VERSION ""
NS_ :

BS_:

BU_: BMS DCM DIM FSM GSM PDM DEBUG

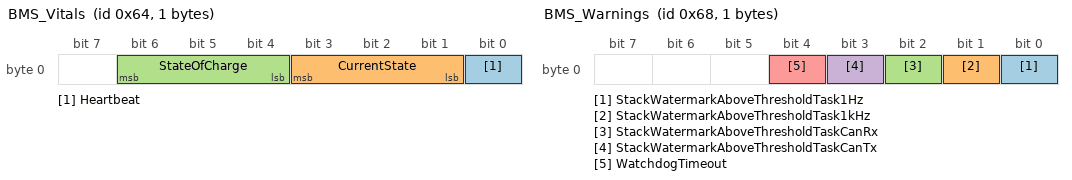
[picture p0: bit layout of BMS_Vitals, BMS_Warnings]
BO_ 100 BMS_Vitals: 1 BMS
SG_ Heartbeat : 0|1@1+ (1,0) [0|1] "" DEBUG,PDM
SG_ CurrentState : 1|3@1+ (1,0) [0|4] "" DEBUG,PDM
SG_ StateOfCharge : 4|3@1+ (14.285714285714286,0) [0|100] "" DEBUG,PDM

BO_ 101 BMS_CanFifoOverflow: 8 BMS
SG_ TxOverflowCount : 0|32@1+ (1,0) [0|4294967295] "" DEBUG
SG_ RxOverflowCount : 32|32@1+ (1,0) [0|4294967295] "" DEBUG

BO_ 103 BMS_WatchdogTimeout: 1 BMS
SG_ TaskName : 0|3@1+ (1,0) [0|4] "" DEBUG

BO_ 104 BMS_Warnings: 1 BMS
SG_ StackWatermarkAboveThresholdTask1Hz : 0|1@1+ (1,0) [0|1] "" DEBUG
SG_ StackWatermarkAboveThresholdTask1kHz : 1|1@1+ (1,0) [0|1] "" DEBUG
SG_ StackWatermarkAboveThresholdTaskCanRx : 2|1@1+ (1,0) [0|1] "" DEBUG
SG_ StackWatermarkAboveThresholdTaskCanTx : 3|1@1+ (1,0) [0|1] "" DEBUG
SG_ WatchdogTimeout : 4|1@1+ (1,0) [0|1] "" DEBUG

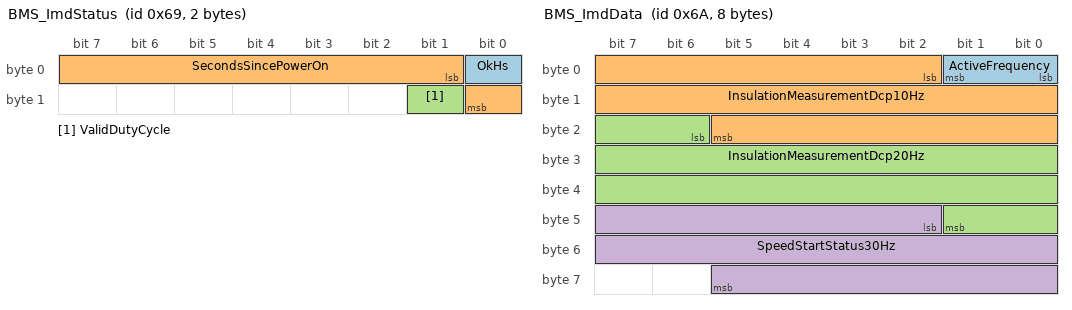
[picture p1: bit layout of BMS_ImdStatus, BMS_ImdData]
BO_ 105 BMS_ImdStatus: 2 BMS
SG_ OkHs : 0|1@1+ (1,0) [0|1] "" DEBUG
SG_ SecondsSincePowerOn : 1|8@1+ (1.0,0) [0|255] "Seconds" DEBUG
SG_ ValidDutyCycle : 9|1@1+ (1,0) [0|1] "" DEBUG

BO_ 106 BMS_ImdData: 8 BMS
SG_ ActiveFrequency : 0|2@1+ (6.666666666666667,0) [0|20] "Hz" DEBUG
SG_ InsulationMeasurementDcp10Hz : 2|20@1+ (0.1,0) [0|65535] "kOhm" DEBUG
SG_ InsulationMeasurementDcp20Hz : 22|20@1+ (0.1,0) [0|65535] "kOhm" DEBUG
SG_ SpeedStartStatus30Hz : 42|20@1+ (0.1,0) [0|65535] "" DEBUG

BO_ 107 BMS_ImdPwmOutput: 1 BMS
SG_ DutyCycle : 0|3@1+ (14.285714285714286,0) [0|100] "%" DEBUG
SG_ Frequency : 3|4@1+ (6.666666666666667,0) [0|100] "Hz" DEBUG

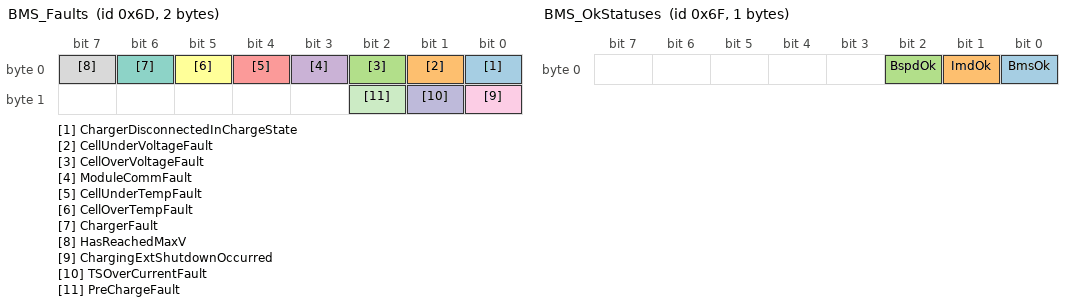
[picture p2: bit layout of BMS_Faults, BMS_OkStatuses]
BO_ 109 BMS_Faults: 2 BMS
SG_ ChargerDisconnectedInChargeState : 0|1@1+ (1,0) [0|1] "" DEBUG
SG_ CellUnderVoltageFault : 1|1@1+ (1,0) [0|1] "" DEBUG
SG_ CellOverVoltageFault : 2|1@1+ (1,0) [0|1] "" DEBUG
SG_ ModuleCommFault : 3|1@1+ (1,0) [0|1] "" DEBUG
SG_ CellUnderTempFault : 4|1@1+ (1,0) [0|1] "" DEBUG
SG_ CellOverTempFault : 5|1@1+ (1,0) [0|1] "" DEBUG
SG_ ChargerFault : 6|1@1+ (1,0) [0|1] "" DEBUG
SG_ HasReachedMaxV : 7|1@1+ (1,0) [0|1] "" DEBUG
SG_ ChargingExtShutdownOccurred : 8|1@1+ (1,0) [0|1] "" DEBUG
SG_ TSOverCurrentFault : 9|1@1+ (1,0) [0|1] "" DEBUG
SG_ PreChargeFault : 10|1@1+ (1,0) [0|1] "" DEBUG

BO_ 110 BMS_Charger: 1 BMS
SG_ IsConnected : 0|1@1+ (1,0) [0|1] "" DEBUG
SG_ IsChargingComplete : 1|1@1+ (1,0) [0|1] "" DEBUG

BO_ 111 BMS_OkStatuses: 1 BMS
SG_ BmsOk : 0|1@1+ (1,0) [0|1] "" DEBUG,DIM
SG_ ImdOk : 1|1@1+ (1,0) [0|1] "" DEBUG,DIM
SG_ BspdOk : 2|1@1+ (1,0) [0|1] "" DEBUG,DIM

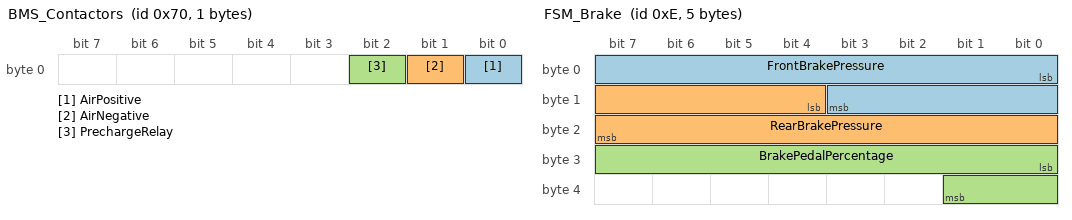
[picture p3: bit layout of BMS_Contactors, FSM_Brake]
BO_ 112 BMS_Contactors: 1 BMS
SG_ AirPositive : 0|1@1+ (1,0) [0|1] "" DEBUG,PDM
SG_ AirNegative : 1|1@1+ (1,0) [0|1] "" DEBUG,PDM
SG_ PrechargeRelay : 2|1@1+ (1,0) [0|1] "" DEBUG,PDM
BO_ 151 FSM_APPs: 3 FSM
SG_ PappsMappedPedalPercentage : 0|10@1+ (0.1,0) [0|100] "%" DEBUG
SG_ SappsMappedPedalPercentage : 10|10@1+ (0.1,0) [0|100] "%" DEBUG

BO_ 113 BMS_MotorShutdownErrors: 1 BMS
SG_ BmsDummyMotorShutdown : 0|1@1+ (1,0) [0|1] "" DEBUG
BO_ 14 FSM_Brake: 5 FSM
SG_ FrontBrakePressure : 0|12@1+ (1,0) [0|2500] "psi" DEBUG
SG_ RearBrakePressure : 12|12@1+ (1,0) [0|2500] "psi" DEBUG
SG_ BrakePedalPercentage : 24|10@1+ (0.1,0) [0|100] "%" DEBUG

BO_ 114 BMS_CellTemperatures: 3 BMS
SG_ MinCellTemperature : 0|10@1+ (0.1,0) [0|100] "degC" DEBUG
SG_ MaxCellTemperature : 10|10@1+ (0.1,0) [0|100] "degC" DEBUG
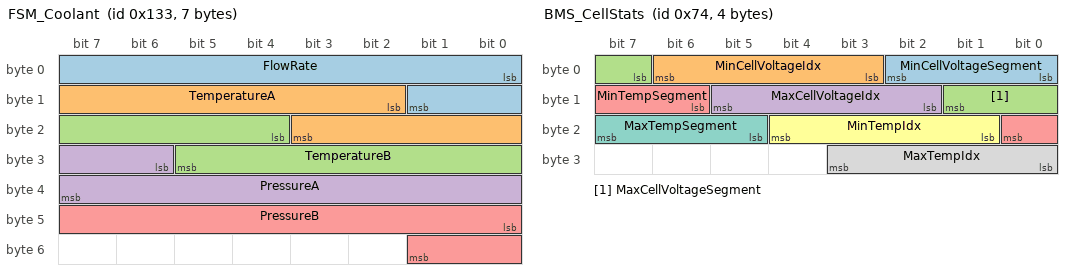
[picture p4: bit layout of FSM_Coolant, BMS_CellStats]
BO_ 307 FSM_Coolant: 7 FSM
SG_ FlowRate : 0|10@1+ (0.1,0) [0|100] "L/min" DEBUG
SG_ TemperatureA : 10|10@1+ (0.1,0) [0|100] "°C" DEBUG
SG_ TemperatureB : 20|10@1+ (0.1,0) [0|100] "°C" DEBUG
SG_ PressureA : 30|10@1+ (0.1,0) [0|100] "psi" DEBUG
SG_ PressureB : 40|10@1+ (0.1,0) [0|100] "psi" DEBUG

BO_ 115 BMS_CellVoltages: 4 BMS
SG_ MinCellVoltage : 0|16@1+ (0.0001,0) [0|5] "V" DEBUG
SG_ MaxCellVoltage : 16|16@1+ (0.0001,0) [0|5] "V" DEBUG

BO_ 116 BMS_CellStats: 4 BMS
SG_ MinCellVoltageSegment : 0|3@1+ (1,0) [0|7] "" DEBUG
SG_ MinCellVoltageIdx : 3|4@1+ (1,0) [0|15] "" DEBUG
SG_ MaxCellVoltageSegment : 7|3@1+ (1.0,0) [0|7] "" DEBUG
SG_ MaxCellVoltageIdx : 10|4@1+ (1,0) [0|15] "" DEBUG
SG_ MinTempSegment : 14|3@1+ (1,0) [0|7] "" DEBUG
SG_ MinTempIdx : 17|4@1+ (1,0) [0|15] "" DEBUG
SG_ MaxTempSegment : 21|3@1+ (1,0) [0|7] "" DEBUG
SG_ MaxTempIdx : 24|4@1+ (1,0) [0|15] "" DEBUG

BO_ 117 BMS_TractiveSystem: 5 BMS
SG_ TsVoltage : 0|23@1+ (0.0001,0) [0|600] "V" DEBUG
SG_ TsCurrent : 23|13@1+ (0.1,-300) [-300|300] "A" DEBUG

BO_ 118 BMS_PackVoltage: 3 BMS
SG_ PackVoltage : 0|23@1+ (0.0001,0) [0|600] "V" DEBUG

BO_ 120 BMS_AvailablePower: 3 BMS
SG_ AvailablePower : 0|20@1+ (0.1,0) [0|100000] "W" DEBUG

BO_ 150 BMS_Alerts: 1 BMS
SG_ BMS_ALERT_DUMMY : 0|1@1+ (1,0) [0|1] "" DEBUG

BO_ 203 DCM_Vitals: 1 DCM
SG_ Heartbeat : 0|1@1+ (1,0) [0|1] "" DEBUG,BMS

BO_ 200 DCM_Alerts: 1 DCM
SG_ DCM_ALERT_DUMMY : 0|1@1+ (1,0) [0|1] "" DEBUG

BO_ 502 DIM_Vitals: 1 DIM
SG_ Heartbeat : 0|1@1+ (1,0) [0|1] "" DEBUG,BMS
SG_ State : 1|1@1+ (1,0) [0|0] "" DEBUG,BMS

BO_ 503 DIM_Switches: 1 DIM
SG_ StartSwitch : 0|1@1+ (1,0) [0|1] "" DEBUG
SG_ AuxSwitch : 1|1@1+ (1,0) [0|1] "" DEBUG

BO_ 504 DIM_Errors: 2 DIM
SG_ TxOverflowCount : 0|8@1+ (1,0) [0|255] "" DEBUG
SG_ RxOverflowCount : 8|8@1+ (1,0) [0|255] "" DEBUG

BO_ 505 DIM_WatchdogTimeout: 1 DIM
SG_ TaskName : 0|3@1+ (1,0) [0|4] "" DEBUG

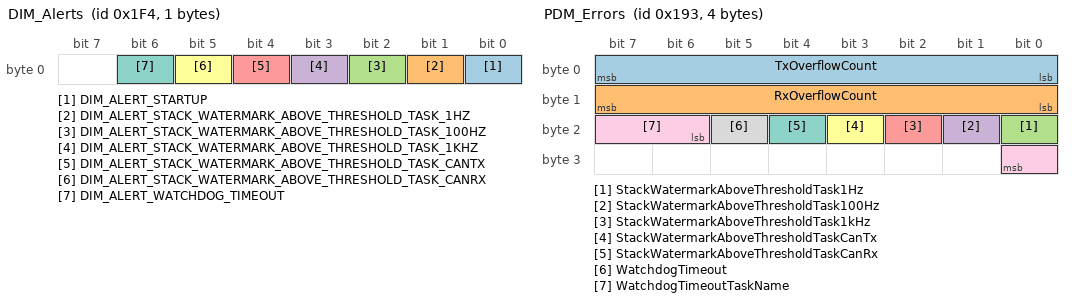
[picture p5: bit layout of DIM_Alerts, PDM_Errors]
BO_ 500 DIM_Alerts: 1 DIM
SG_ DIM_ALERT_STARTUP : 0|1@1+ (1,0) [0|1] "" DEBUG
SG_ DIM_ALERT_STACK_WATERMARK_ABOVE_THRESHOLD_TASK_1HZ : 1|1@1+ (1,0) [0|1] "" DEBUG
SG_ DIM_ALERT_STACK_WATERMARK_ABOVE_THRESHOLD_TASK_100HZ : 2|1@1+ (1,0) [0|1] "" DEBUG
SG_ DIM_ALERT_STACK_WATERMARK_ABOVE_THRESHOLD_TASK_1KHZ : 3|1@1+ (1,0) [0|1] "" DEBUG
SG_ DIM_ALERT_STACK_WATERMARK_ABOVE_THRESHOLD_TASK_CANTX : 4|1@1+ (1,0) [0|1] "" DEBUG
SG_ DIM_ALERT_STACK_WATERMARK_ABOVE_THRESHOLD_TASK_CANRX : 5|1@1+ (1,0) [0|1] "" DEBUG
SG_ DIM_ALERT_WATCHDOG_TIMEOUT : 6|1@1+ (1,0) [0|1] "" DEBUG

BO_ 303 FSM_Vitals: 1 FSM
SG_ Heartbeat : 0|1@1+ (1,0) [0|1] "" DEBUG,BMS

BO_ 300 FSM_Alerts: 1 FSM
SG_ PDM_ALERT_DUMMY : 0|1@1+ (1,0) [0|1] "" DEBUG

BO_ 318 FSM_Steering: 2 FSM
SG_ SteeringAngle : 0|12@1+ (0.1,-110) [-110|110] "deg" DEBUG

BO_ 300 FSM_AlertSet: 1 FSM
SG_ FSM_AlertSet : 0|5@1+ (1,0) [0|31] "" DEBUG

BO_ 301 FSM_AlertCleared: 1 FSM
SG_ FSM_AlertCleared : 0|5@1+ (1,0) [0|31] "" DEBUG

BO_ 603 GSM_Test1: 1 GSM
SG_ Ex1 : 0|1@1+ (1,0) [0|1] "" DEBUG

BO_ 600 GSM_Alerts: 1 GSM
SG_ GSM_ALERT_DUMMY : 0|1@1+ (1,0) [0|1] "" DEBUG

BO_ 402 PDM_Vitals: 1 PDM
SG_ Heartbeat : 0|1@1+ (1,0) [0|1] "" DEBUG,BMS
SG_ State : 1|1@1+ (1,0) [0|0] "" DEBUG,BMS

BO_ 403 PDM_Errors: 4 PDM
SG_ TxOverflowCount : 0|8@1+ (1,0) [0|255] "" DEBUG
SG_ RxOverflowCount : 8|8@1+ (1,0) [0|255] "" DEBUG
SG_ StackWatermarkAboveThresholdTask1Hz : 16|1@1+ (1,0) [0|1] "" DEBUG
SG_ StackWatermarkAboveThresholdTask100Hz : 17|1@1+ (1,0) [0|1] "" DEBUG
SG_ StackWatermarkAboveThresholdTask1kHz : 18|1@1+ (1,0) [0|1] "" DEBUG
SG_ StackWatermarkAboveThresholdTaskCanTx : 19|1@1+ (1,0) [0|1] "" DEBUG
SG_ StackWatermarkAboveThresholdTaskCanRx : 20|1@1+ (1,0) [0|1] "" DEBUG
SG_ WatchdogTimeout : 21|1@1+ (1,0) [0|1] "" DEBUG
SG_ WatchdogTimeoutTaskName : 22|3@1+ (1,0) [0|4] "" DEBUG

BO_ 400 PDM_Alerts: 1 PDM
SG_ PDM_ALERT_STARTUP : 0|1@1+ (1,0) [0|1] "" DEBUG
SG_ PDM_ALERT_WATCHDOG_TIMEOUT : 1|1@1+ (1,0) [0|1] "" DEBUG

BA_DEF_  "BusType" STRING ;
BA_DEF_DEF_  "BusType" "CAN";

BA_ "GenSigStartValue" SG_ 100 Heartbeat 0;
BA_ "GenSigStartValue" SG_ 100 CurrentState 0;
BA_ "GenSigStartValue" SG_ 100 StateOfCharge 0;
BA_ "GenSigStartValue" SG_ 101 TxOverflowCount 0;
BA_ "GenSigStartValue" SG_ 101 RxOverflowCount 0;
BA_ "GenSigStartValue" SG_ 103 TaskName 0;
BA_ "GenSigStartValue" SG_ 104 StackWatermarkAboveThresholdTask1Hz 0;
BA_ "GenSigStartValue" SG_ 104 StackWatermarkAboveThresholdTask1kHz 0;
BA_ "GenSigStartValue" SG_ 104 StackWatermarkAboveThresholdTaskCanRx 0;
BA_ "GenSigStartValue" SG_ 104 StackWatermarkAboveThresholdTaskCanTx 0;
BA_ "GenSigStartValue" SG_ 104 WatchdogTimeout 0;
BA_ "GenSigStartValue" SG_ 105 OkHs 0;
BA_ "GenSigStartValue" SG_ 105 SecondsSincePowerOn 0;
BA_ "GenSigStartValue" SG_ 105 ValidDutyCycle 0;
BA_ "GenSigStartValue" SG_ 106 ActiveFrequency 0;
BA_ "GenSigStartValue" SG_ 106 InsulationMeasurementDcp10Hz 0;
BA_ "GenSigStartValue" SG_ 106 InsulationMeasurementDcp20Hz 0;
BA_ "GenSigStartValue" SG_ 106 SpeedStartStatus30Hz 0;
BA_ "GenSigStartValue" SG_ 107 DutyCycle 0;
BA_ "GenSigStartValue" SG_ 107 Frequency 0;
BA_ "GenSigStartValue" SG_ 109 ChargerDisconnectedInChargeState 0;
BA_ "GenSigStartValue" SG_ 109 CellUnderVoltageFault 0;
BA_ "GenSigStartValue" SG_ 109 CellOverVoltageFault 0;
BA_ "GenSigStartValue" SG_ 109 ModuleCommFault 0;
BA_ "GenSigStartValue" SG_ 109 CellUnderTempFault 0;
BA_ "GenSigStartValue" SG_ 109 CellOverTempFault 0;
BA_ "GenSigStartValue" SG_ 109 ChargerFault 0;
BA_ "GenSigStartValue" SG_ 109 HasReachedMaxV 0;
BA_ "GenSigStartValue" SG_ 109 ChargingExtShutdownOccurred 0;
BA_ "GenSigStartValue" SG_ 109 TSOverCurrentFault 0;
BA_ "GenSigStartValue" SG_ 109 PreChargeFault 0;
BA_ "GenSigStartValue" SG_ 110 IsConnected 0;
BA_ "GenSigStartValue" SG_ 110 IsChargingComplete 0;
BA_ "GenSigStartValue" SG_ 111 BmsOk 0;
BA_ "GenSigStartValue" SG_ 111 ImdOk 0;
BA_ "GenSigStartValue" SG_ 111 BspdOk 0;
BA_ "GenSigStartValue" SG_ 112 AirPositive 0;
BA_ "GenSigStartValue" SG_ 112 AirNegative 0;
BA_ "GenSigStartValue" SG_ 112 PrechargeRelay 0;
BA_ "GenSigStartValue" SG_ 113 BmsDummyMotorShutdown 0;
BA_ "GenSigStartValue" SG_ 114 MinCellTemperature 0;
BA_ "GenSigStartValue" SG_ 114 MaxCellTemperature 0;
BA_ "GenSigStartValue" SG_ 115 MinCellVoltage 0;
BA_ "GenSigStartValue" SG_ 115 MaxCellVoltage 0;
BA_ "GenSigStartValue" SG_ 116 MinCellVoltageSegment 0;
BA_ "GenSigStartValue" SG_ 116 MinCellVoltageIdx 0;
BA_ "GenSigStartValue" SG_ 116 MaxCellVoltageSegment 0;
BA_ "GenSigStartValue" SG_ 116 MaxCellVoltageIdx 0;
BA_ "GenSigStartValue" SG_ 116 MinTempSegment 0;
BA_ "GenSigStartValue" SG_ 116 MinTempIdx 0;
BA_ "GenSigStartValue" SG_ 116 MaxTempSegment 0;
BA_ "GenSigStartValue" SG_ 116 MaxTempIdx 0;
BA_ "GenSigStartValue" SG_ 117 TsVoltage 0;
BA_ "GenSigStartValue" SG_ 117 TsCurrent -300;
BA_ "GenSigStartValue" SG_ 118 PackVoltage 0;
BA_ "GenSigStartValue" SG_ 120 AvailablePower 0;
BA_ "GenSigStartValue" SG_ 150 BMS_ALERT_DUMMY 0;
BA_ "GenSigStartValue" SG_ 203 Heartbeat 0;
BA_ "GenSigStartValue" SG_ 200 DCM_ALERT_DUMMY 0;
BA_ "GenSigStartValue" SG_ 502 Heartbeat 0;
BA_ "GenSigStartValue" SG_ 502 State 0;
BA_ "GenSigStartValue" SG_ 503 StartSwitch 0;
BA_ "GenSigStartValue" SG_ 503 AuxSwitch 0;
BA_ "GenSigStartValue" SG_ 504 TxOverflowCount 0;
BA_ "GenSigStartValue" SG_ 504 RxOverflowCount 0;
BA_ "GenSigStartValue" SG_ 505 TaskName 0;
BA_ "GenSigStartValue" SG_ 500 DIM_ALERT_STARTUP 0;
BA_ "GenSigStartValue" SG_ 500 DIM_ALERT_STACK_WATERMARK_ABOVE_THRESHOLD_TASK_1HZ 0;
BA_ "GenSigStartValue" SG_ 500 DIM_ALERT_STACK_WATERMARK_ABOVE_THRESHOLD_TASK_100HZ 0;
BA_ "GenSigStartValue" SG_ 500 DIM_ALERT_STACK_WATERMARK_ABOVE_THRESHOLD_TASK_1KHZ 0;
BA_ "GenSigStartValue" SG_ 500 DIM_ALERT_STACK_WATERMARK_ABOVE_THRESHOLD_TASK_CANTX 0;
BA_ "GenSigStartValue" SG_ 500 DIM_ALERT_STACK_WATERMARK_ABOVE_THRESHOLD_TASK_CANRX 0;
BA_ "GenSigStartValue" SG_ 500 DIM_ALERT_WATCHDOG_TIMEOUT 0;
BA_ "GenSigStartValue" SG_ 303 Heartbeat 0;
BA_ "GenSigStartValue" SG_ 300 PDM_ALERT_DUMMY 0;
BA_ "GenSigStartValue" SG_ 102 Ex1 0;
BA_ "GenSigStartValue" SG_ 100 BMS_AlertSet 0;
BA_ "GenSigStartValue" SG_ 101 BMS_AlertCleared 0;
BA_ "GenSigStartValue" SG_ 202 Ex1 0;
BA_ "GenSigStartValue" SG_ 200 DCM_AlertSet 0;
BA_ "GenSigStartValue" SG_ 201 DCM_AlertCleared 0;
BA_ "GenSigStartValue" SG_ 502 Ex1 0;
BA_ "GenSigStartValue" SG_ 502 Ex2 0;
BA_ "GenSigStartValue" SG_ 503 Ex3 0;
BA_ "GenSigStartValue" SG_ 503 Ex4 0;
BA_ "GenSigStartValue" SG_ 503 Ex5 -120;
BA_ "GenSigStartValue" SG_ 500 DIM_AlertSet 0;
BA_ "GenSigStartValue" SG_ 501 DIM_AlertCleared 0;
BA_ "GenSigStartValue" SG_ 151 PappsMappedPedalPercentage 0;
BA_ "GenSigStartValue" SG_ 151 SappsMappedPedalPercentage 0;
BA_ "GenSigStartValue" SG_ 14 FrontBrakePressure 0;
BA_ "GenSigStartValue" SG_ 14 RearBrakePressure 0;
BA_ "GenSigStartValue" SG_ 14 BrakePedalPercentage 0;
BA_ "GenSigStartValue" SG_ 307 FlowRate 0;
BA_ "GenSigStartValue" SG_ 307 TemperatureA 0;
BA_ "GenSigStartValue" SG_ 307 TemperatureB 0;
BA_ "GenSigStartValue" SG_ 307 PressureA 0;
BA_ "GenSigStartValue" SG_ 307 PressureB 0;
BA_ "GenSigStartValue" SG_ 318 SteeringAngle -110;
BA_ "GenSigStartValue" SG_ 300 FSM_AlertSet 0;
BA_ "GenSigStartValue" SG_ 301 FSM_AlertCleared 0;
BA_ "GenSigStartValue" SG_ 603 Ex1 0;
BA_ "GenSigStartValue" SG_ 600 GSM_ALERT_DUMMY 0;
BA_ "GenSigStartValue" SG_ 402 Heartbeat 0;
BA_ "GenSigStartValue" SG_ 402 State 0;
BA_ "GenSigStartValue" SG_ 403 TxOverflowCount 0;
BA_ "GenSigStartValue" SG_ 403 RxOverflowCount 0;
BA_ "GenSigStartValue" SG_ 403 StackWatermarkAboveThresholdTask1Hz 0;
BA_ "GenSigStartValue" SG_ 403 StackWatermarkAboveThresholdTask100Hz 0;
BA_ "GenSigStartValue" SG_ 403 StackWatermarkAboveThresholdTask1kHz 0;
BA_ "GenSigStartValue" SG_ 403 StackWatermarkAboveThresholdTaskCanTx 0;
BA_ "GenSigStartValue" SG_ 403 StackWatermarkAboveThresholdTaskCanRx 0;
BA_ "GenSigStartValue" SG_ 403 WatchdogTimeout 0;
BA_ "GenSigStartValue" SG_ 403 WatchdogTimeoutTaskName 0;
BA_ "GenSigStartValue" SG_ 400 PDM_ALERT_STARTUP 0;
BA_ "GenSigStartValue" SG_ 400 PDM_ALERT_WATCHDOG_TIMEOUT 0;

BA_ "GenMsgCycleTime" BO_ 100  100;
BA_ "GenMsgCycleTime" BO_ 101  5000;
BA_ "GenMsgCycleTime" BO_ 103  1000;
BA_ "GenMsgCycleTime" BO_ 104  1000;
BA_ "GenMsgCycleTime" BO_ 105  1000;
BA_ "GenMsgCycleTime" BO_ 106  1000;
BA_ "GenMsgCycleTime" BO_ 107  1000;
BA_ "GenMsgCycleTime" BO_ 109  1000;
BA_ "GenMsgCycleTime" BO_ 110  1000;
BA_ "GenMsgCycleTime" BO_ 111  10;
BA_ "GenMsgCycleTime" BO_ 112  10;
BA_ "GenMsgCycleTime" BO_ 113  1000;
BA_ "GenMsgCycleTime" BO_ 114  100;
BA_ "GenMsgCycleTime" BO_ 115  100;
BA_ "GenMsgCycleTime" BO_ 116  100;
BA_ "GenMsgCycleTime" BO_ 117  100;
BA_ "GenMsgCycleTime" BO_ 118  100;
BA_ "GenMsgCycleTime" BO_ 120  100;
BA_ "GenMsgCycleTime" BO_ 203  1000;
BA_ "GenMsgCycleTime" BO_ 502  1000;
BA_ "GenMsgCycleTime" BO_ 503  1000;
BA_ "GenMsgCycleTime" BO_ 504  1000;
BA_ "GenMsgCycleTime" BO_ 303  1000;
BA_ "GenMsgCycleTime" BO_ 503  10;
BA_ "GenMsgCycleTime" BO_ 151  100;
BA_ "GenMsgCycleTime" BO_ 14  10;
BA_ "GenMsgCycleTime" BO_ 307  1000;
BA_ "GenMsgCycleTime" BO_ 318  100;
BA_ "GenMsgCycleTime" BO_ 603  1000;
BA_ "GenMsgCycleTime" BO_ 402  1000;
BA_ "GenMsgCycleTime" BO_ 403  1000;

VAL_ 100 CurrentState 0 "BMS_INIT_STATE" 1 "BMS_PRECHARGE_STATE" 2 "BMS_CHARGE_STATE" 3 "BMS_DRIVE_STATE" 4 "BMS_FAULT_STATE";
VAL_ 103 TaskName 0 "RTOS_TASK_1HZ" 1 "RTOS_TASK_100HZ" 2 "RTOS_TASK_1KHZ" 3 "RTOS_TASK_CAN_TX" 4 "RTOS_TASK_CAN_RX";
VAL_ 112 AirPositive 0 "CONTACTOR_STATE_OPEN" 1 "CONTACTOR_STATE_CLOSED";
VAL_ 112 AirNegative 0 "CONTACTOR_STATE_OPEN" 1 "CONTACTOR_STATE_CLOSED";
VAL_ 112 PrechargeRelay 0 "CONTACTOR_STATE_OPEN" 1 "CONTACTOR_STATE_CLOSED";
VAL_ 502 State 0 "DIM_STATE_DRIVE";
VAL_ 503 StartSwitch 0 "SWITCH_OFF" 1 "SWITCH_ON";
VAL_ 503 AuxSwitch 0 "SWITCH_OFF" 1 "SWITCH_ON";
VAL_ 505 TaskName 0 "RTOS_TASK_1HZ" 1 "RTOS_TASK_100HZ" 2 "RTOS_TASK_1KHZ" 3 "RTOS_TASK_CAN_TX" 4 "RTOS_TASK_CAN_RX";
VAL_ 402 State 0 "PDM_STATE_DRIVE";
VAL_ 403 WatchdogTimeoutTaskName 0 "RTOS_TASK_1HZ" 1 "RTOS_TASK_100HZ" 2 "RTOS_TASK_1KHZ" 3 "RTOS_TASK_CAN_TX" 4 "RTOS_TASK_CAN_RX";
VAL_ 100 BMS_AlertSet 0 "NUM_BMS_ALERTS";
VAL_ 101 BMS_AlertCleared 0 "NUM_BMS_ALERTS";
VAL_ 200 DCM_AlertSet 0 "NUM_DCM_ALERTS";
VAL_ 201 DCM_AlertCleared 0 "NUM_DCM_ALERTS";
VAL_ 503 Ex4 0 "CHOICE_0" 1 "CHOICE_1" 2 "CHOICE_2";
VAL_ 500 DIM_AlertSet 0 "NUM_DIM_ALERTS";
VAL_ 501 DIM_AlertCleared 0 "NUM_DIM_ALERTS";
VAL_ 300 FSM_AlertSet 0 "PAPPS_OCSC_IS_ACTIVE" 1 "SAPPS_OCSC_IS_ACTIVE" 2 "FLOW_METER_UNDERFLOW" 3 "TORQUE_PLAUSIBILITY_CHECK_FAILED" 4 "Brake_Acc_Disagreement" 5 "NUM_FSM_ALERTS";
VAL_ 301 FSM_AlertCleared 0 "PAPPS_OCSC_IS_ACTIVE" 1 "SAPPS_OCSC_IS_ACTIVE" 2 "FLOW_METER_UNDERFLOW" 3 "TORQUE_PLAUSIBILITY_CHECK_FAILED" 4 "Brake_Acc_Disagreement" 5 "NUM_FSM_ALERTS";
VAL_ 600 GSM_AlertSet 0 "NUM_GSM_ALERTS";
VAL_ 601 GSM_AlertCleared 0 "NUM_GSM_ALERTS";
VAL_ 400 PDM_AlertSet 0 "NUM_PDM_ALERTS";
VAL_ 401 PDM_AlertCleared 0 "NUM_PDM_ALERTS";
